AUTOSAR XML (schema 00046)
package /SWCs/SWCs_EABS
  sensor actuator sw component type SWC1_SA_LidarSensor
    provide port P1_LidarData: provided-interface=SRI_u32
  sensor actuator sw component type SWC2_SA_SpeedSensor
    provide port P3_speedData: provided-interface=SRI_u32
  sensor actuator sw component type SWC6_SA_WarningLED
    require port P6_warningLedIndicator: required-interface=SRI_bool
  ecu abstraction sw component type SWC3_ECABS_IO_Abstraction
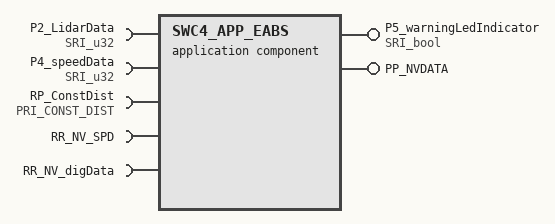
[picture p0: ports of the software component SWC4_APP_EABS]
  application sw component type SWC4_APP_EABS
    require port P2_LidarData: required-interface=SRI_u32
    require port P4_speedData: required-interface=SRI_u32
    provide port P5_warningLedIndicator: provided-interface=SRI_bool
    require port RP_ConstDist: required-interface=PRI_CONST_DIST
    provide port PP_NVDATA: nv-data-port-annotation=NVI_Data
    require port RR_NV_SPD: client-server-annotation=NVI_Speed
    require port RR_NV_digData: client-server-annotation=NVI_DigData
  parameter sw component type SWC5_PARM_DistanceParameters
    provide port PP_ConstDist: provided-interface=PRI_CONST_DIST
  complex device driver sw component type SWC7_CDD_Braking
  service sw component type SWC8_SRVS_DigM
    provide port PR_NV_digData: client-server-annotation=NVI_DigData
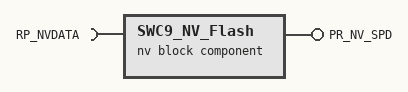
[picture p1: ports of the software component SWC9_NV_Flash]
  nv block sw component type SWC9_NV_Flash
    require port RP_NVDATA: nv-data-port-annotation=NVI_Data
    provide port PR_NV_SPD: client-server-annotation=NVI_Speed
